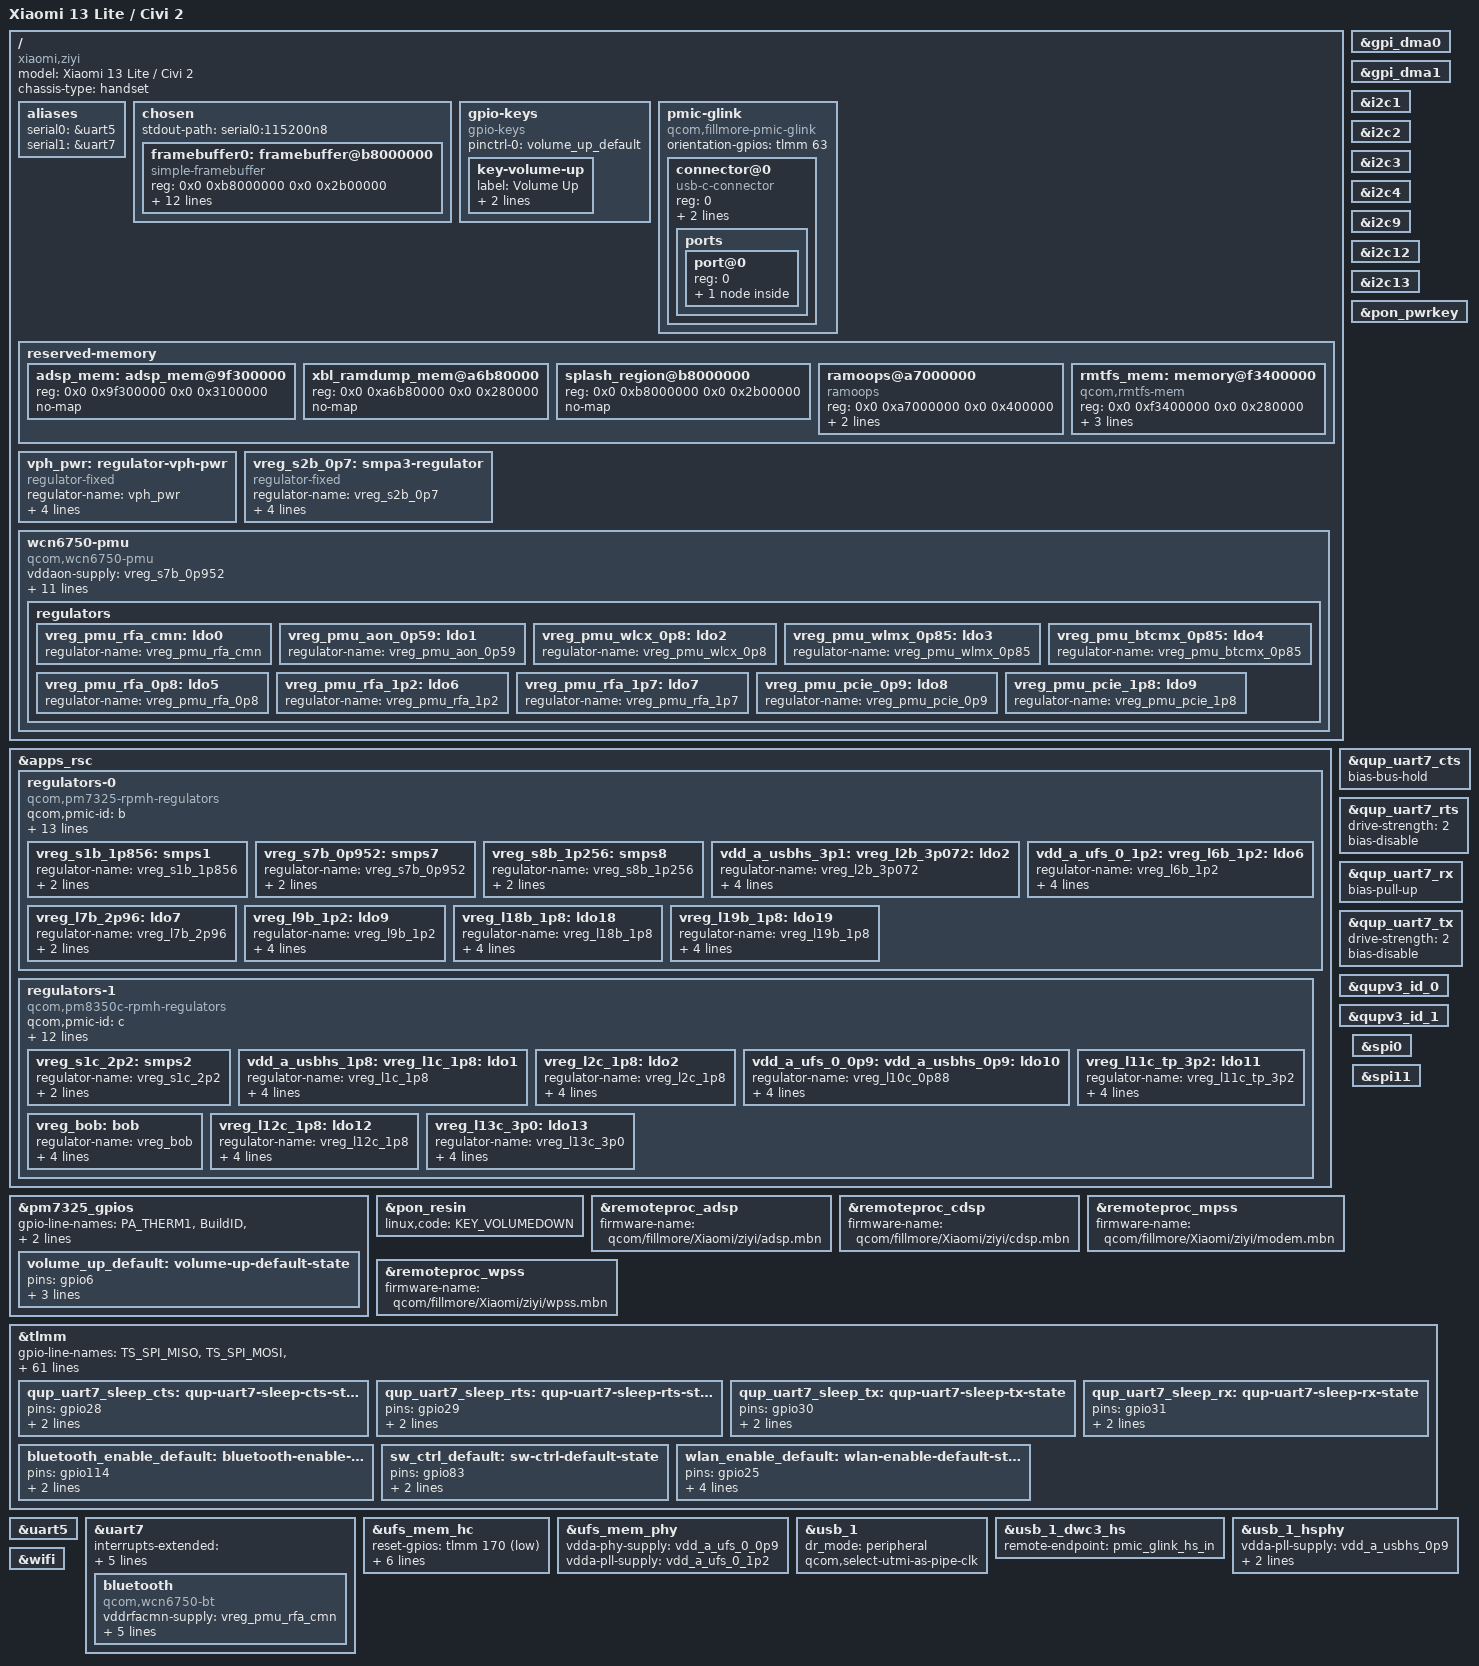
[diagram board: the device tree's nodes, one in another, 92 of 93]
// SPDX-License-Identifier: GPL-2.0-only
/*
 * Copyright (c) 2025, Aelin Reidel <aelin@mainlining.org>
 */

/dts-v1/;

#include <dt-bindings/pinctrl/qcom,pmic-gpio.h>
#include <dt-bindings/regulator/qcom,rpmh-regulator.h>
#include "fillmore.dtsi"
#include "pm7325.dtsi"
#include "pm8350c.dtsi"
#include "pmk8350.dtsi"

/delete-node/ &adsp_mem;
/delete-node/ &rmtfs_mem;
/delete-node/ &xbl_ramdump_mem;

/ {
	model = "Xiaomi 13 Lite / Civi 2";
	compatible = "xiaomi,ziyi", "qcom,fillmore";
	chassis-type = "handset";

	aliases {
		serial0 = &uart5;
		serial1 = &uart7;
	};

	chosen {
		#address-cells = <2>;
		#size-cells = <2>;
		ranges;

		stdout-path = "serial0:115200n8";

		framebuffer0: framebuffer@b8000000 {
			compatible = "simple-framebuffer";
			reg = <0x0 0xb8000000 0x0 0x2b00000>;
			width = <1080>;
			height = <2400>;
			stride = <(1080 * 4)>;
			format = "a8r8g8b8";

			clocks = <&gcc GCC_DISP_HF_AXI_CLK>,
				 <&gcc GCC_DISP_SF_AXI_CLK>,
				 <&dispcc DISP_CC_MDSS_MDP_CLK>,
				 <&dispcc DISP_CC_MDSS_BYTE0_CLK>,
				 <&dispcc DISP_CC_MDSS_BYTE0_INTF_CLK>,
				 <&dispcc DISP_CC_MDSS_PCLK0_CLK>,
				 <&dispcc DISP_CC_MDSS_VSYNC_CLK>;
			power-domains = <&dispcc DISP_CC_MDSS_CORE_GDSC>;
		};
	};

	gpio-keys {
		compatible = "gpio-keys";

		pinctrl-0 = <&volume_up_default>;
		pinctrl-names = "default";

		key-volume-up {
			label = "Volume Up";
			gpios = <&pm7325_gpios 6 GPIO_ACTIVE_LOW>;
			linux,code = <KEY_VOLUMEUP>;
		};
	};

	pmic-glink {
		compatible = "qcom,fillmore-pmic-glink",
			     "qcom,sm8450-pmic-glink",
			     "qcom,pmic-glink";
		#address-cells = <1>;
		#size-cells = <0>;
		orientation-gpios = <&tlmm 63 GPIO_ACTIVE_HIGH>;

		connector@0 {
			compatible = "usb-c-connector";
			reg = <0>;

			power-role = "dual";
			data-role = "dual";

			ports {
				#address-cells = <1>;
				#size-cells = <0>;

				port@0 {
					reg = <0>;

					pmic_glink_hs_in: endpoint {
						remote-endpoint = <&usb_1_dwc3_hs>;
					};
				};
			};
		};
	};

	reserved-memory {
		adsp_mem: adsp_mem@9f300000 {
			reg = <0x0 0x9f300000 0x0 0x3100000>;
			no-map;
		};

		xbl_ramdump_mem@a6b80000 {
			reg = <0x0 0xa6b80000 0x0 0x280000>;
			no-map;
		};

		splash_region@b8000000 {
			reg = <0x0 0xb8000000 0x0 0x2b00000>;
			no-map;
		};

		ramoops@a7000000 {
			compatible = "ramoops";
			reg = <0x0 0xa7000000 0x0 0x400000>;
			console-size = <0x200000>;
			pmsg-size = <0x200000>;
		};

		rmtfs_mem: memory@f3400000 {
			compatible = "qcom,rmtfs-mem";
			reg = <0x0 0xf3400000 0x0 0x280000>;
			no-map;

			qcom,client-id = <1>;
			qcom,vmid = <QCOM_SCM_VMID_MSS_MSA>;
		};
	};

	vph_pwr: regulator-vph-pwr {
		compatible = "regulator-fixed";

		regulator-name = "vph_pwr";
		regulator-min-microvolt = <3700000>;
		regulator-max-microvolt = <3700000>;

		regulator-always-on;
		regulator-boot-on;
	};

	/* S2B is really ebi.lvl but it's there for supply map completeness sake */
	vreg_s2b_0p7: smpa3-regulator {
		compatible = "regulator-fixed";
		regulator-name = "vreg_s2b_0p7";

		regulator-min-microvolt = <65535>;
		regulator-max-microvolt = <65535>;
		regulator-always-on;
		vin-supply = <&vph_pwr>;
	};

	wcn6750-pmu {
		compatible = "qcom,wcn6750-pmu";

		vddaon-supply = <&vreg_s7b_0p952>;
		vddasd-supply = <&vreg_l11c_tp_3p2>;
		vddpmu-supply = <&vreg_s7b_0p952>;
		vddrfa0p8-supply = <&vreg_s7b_0p952>;
		vddrfa1p2-supply = <&vreg_s8b_1p256>;
		vddrfa1p7-supply = <&vreg_s1b_1p856>;
		vddrfa2p2-supply = <&vreg_s1c_2p2>;

		wlan-enable-gpios = <&tlmm 25 GPIO_ACTIVE_HIGH>;
		bt-enable-gpios = <&tlmm 114 GPIO_ACTIVE_HIGH>;
		swctrl-gpios = <&tlmm 83 GPIO_ACTIVE_HIGH>;

		pinctrl-0 = <&bluetooth_enable_default>, <&wlan_enable_default>, <&sw_ctrl_default>;
		pinctrl-names = "default";

		regulators {
			vreg_pmu_rfa_cmn: ldo0 {
				regulator-name = "vreg_pmu_rfa_cmn";
			};

			vreg_pmu_aon_0p59: ldo1 {
				regulator-name = "vreg_pmu_aon_0p59";
			};

			vreg_pmu_wlcx_0p8: ldo2 {
				regulator-name = "vreg_pmu_wlcx_0p8";
			};

			vreg_pmu_wlmx_0p85: ldo3 {
				regulator-name = "vreg_pmu_wlmx_0p85";
			};

			vreg_pmu_btcmx_0p85: ldo4 {
				regulator-name = "vreg_pmu_btcmx_0p85";
			};

			vreg_pmu_rfa_0p8: ldo5 {
				regulator-name = "vreg_pmu_rfa_0p8";
			};

			vreg_pmu_rfa_1p2: ldo6 {
				regulator-name = "vreg_pmu_rfa_1p2";
			};

			vreg_pmu_rfa_1p7: ldo7 {
				regulator-name = "vreg_pmu_rfa_1p7";
			};

			vreg_pmu_pcie_0p9: ldo8 {
				regulator-name = "vreg_pmu_pcie_0p9";
			};

			vreg_pmu_pcie_1p8: ldo9 {
				regulator-name = "vreg_pmu_pcie_1p8";
			};
		};
	};
};

&apps_rsc {
	regulators-0 {
		compatible = "qcom,pm7325-rpmh-regulators";
		qcom,pmic-id = "b";

		vdd-s1-supply = <&vph_pwr>;
		vdd-s2-supply = <&vph_pwr>;
		vdd-s7-supply = <&vph_pwr>;
		vdd-s8-supply = <&vph_pwr>;

		vdd-l1-l4-l12-l15-supply = <&vreg_s7b_0p952>;
		vdd-l2-l7-supply = <&vreg_bob>;
		vdd-l3-supply = <&vreg_s2b_0p7>;
		vdd-l5-supply = <&vreg_s2b_0p7>;
		vdd-l6-l9-l10-supply = <&vreg_s8b_1p256>;
		vdd-l8-supply = <&vreg_s7b_0p952>;
		vdd-l11-l17-l18-l19-supply = <&vreg_s1b_1p856>;
		vdd-l13-supply = <&vreg_s7b_0p952>;
		vdd-l14-l16-supply = <&vreg_s8b_1p256>;

		/*
		 * S2, L4-L5 are ARCs:
		 * S2 - ebi.lvl,
		 * L4 - lmx.lvl,
		 * l5 - lcx.lvl.
		 *
		 * L10 is unused.
		 */

		vreg_s1b_1p856: smps1 {
			regulator-name = "vreg_s1b_1p856";
			regulator-min-microvolt = <1700000>;
			regulator-max-microvolt = <2040000>;
		};

		vreg_s7b_0p952: smps7 {
			regulator-name = "vreg_s7b_0p952";
			regulator-min-microvolt = <598000>;
			regulator-max-microvolt = <1120000>;
		};

		vreg_s8b_1p256: smps8 {
			regulator-name = "vreg_s8b_1p256";
			regulator-min-microvolt = <382000>;
			regulator-max-microvolt = <1510000>;
		};

		vdd_a_usbhs_3p1:
		vreg_l2b_3p072: ldo2 {
			regulator-name = "vreg_l2b_3p072";
			regulator-min-microvolt = <2700000>;
			regulator-max-microvolt = <3544000>;
			regulator-initial-mode = <RPMH_REGULATOR_MODE_HPM>;
		};

		vdd_a_ufs_0_1p2:
		vreg_l6b_1p2: ldo6 {
			regulator-name = "vreg_l6b_1p2";
			regulator-min-microvolt = <1140000>;
			regulator-max-microvolt = <1260000>;
			regulator-initial-mode = <RPMH_REGULATOR_MODE_HPM>;
		};

		vreg_l7b_2p96: ldo7 {
			regulator-name = "vreg_l7b_2p96";
			/*
			 * Remove min/max voltages for this regulator as initial
			 * voltage of L7B is set to be 2.504v/2.952v during PON
			 * depending upon the UFS mode 3.x/2.x. UFS is the only
			 * client on this and this regulator will only be voted
			 * for enabling/disabling conditions.
			 */
			regulator-initial-mode = <RPMH_REGULATOR_MODE_HPM>;
		};

		vreg_l9b_1p2: ldo9 {
			regulator-name = "vreg_l9b_1p2";
			regulator-min-microvolt = <1080000>;
			regulator-max-microvolt = <1304000>;
			regulator-initial-mode = <RPMH_REGULATOR_MODE_HPM>;
		};

		vreg_l18b_1p8: ldo18 {
			regulator-name = "vreg_l18b_1p8";
			regulator-min-microvolt = <1504000>;
			regulator-max-microvolt = <2000000>;
			regulator-initial-mode = <RPMH_REGULATOR_MODE_HPM>;
		};

		vreg_l19b_1p8: ldo19 {
			regulator-name = "vreg_l19b_1p8";
			regulator-min-microvolt = <1700000>;
			regulator-max-microvolt = <1950000>;
			regulator-initial-mode = <RPMH_REGULATOR_MODE_HPM>;
		};
	};

	regulators-1 {
		compatible = "qcom,pm8350c-rpmh-regulators";
		qcom,pmic-id = "c";

		vdd-s1-supply = <&vph_pwr>;
		vdd-s2-supply = <&vph_pwr>;
		vdd-s5-supply = <&vph_pwr>;
		vdd-s7-supply = <&vph_pwr>;
		vdd-s9-supply = <&vph_pwr>;
		vdd-s10-supply = <&vph_pwr>;

		vdd-l1-l12-supply = <&vreg_s1b_1p856>;
		vdd-l2-l8-supply = <&vreg_s1b_1p856>;
		vdd-l3-l4-l5-l7-l13-supply = <&vreg_bob>;
		vdd-l6-l9-l11-supply = <&vreg_bob>;
		vdd-l10-supply = <&vreg_s7b_0p952>;

		vdd-bob-supply = <&vph_pwr>;

		/*
		 * S2, S4, S5, S6, S8, S10 are ARCs:
		 * S2  - gfx.lvl,
		 * S4  - mxc.lvl,
		 * S5  - mmcx.lvl,
		 * S6  - mms.lvl,
		 * S8  - cx.lvl,
		 * S10 - mx.lvl.
		 */

		vreg_s1c_2p2: smps2 {
			regulator-name = "vreg_s1c_2p2";
			regulator-min-microvolt = <850000>;
			regulator-max-microvolt = <2200000>;
		};

		vdd_a_usbhs_1p8:
		vreg_l1c_1p8: ldo1 {
			regulator-name = "vreg_l1c_1p8";
			regulator-min-microvolt = <1620000>;
			regulator-max-microvolt = <1980000>;
			regulator-initial-mode = <RPMH_REGULATOR_MODE_HPM>;
		};

		vreg_l2c_1p8: ldo2 {
			regulator-name = "vreg_l2c_1p8";
			regulator-min-microvolt = <1620000>;
			regulator-max-microvolt = <1980000>;
			regulator-initial-mode = <RPMH_REGULATOR_MODE_HPM>;
		};

		vdd_a_ufs_0_0p9:
		vdd_a_usbhs_0p9:
		vreg_l10c_0p88: ldo10 {
			regulator-name = "vreg_l10c_0p88";
			regulator-min-microvolt = <720000>;
			regulator-max-microvolt = <1050000>;
			regulator-initial-mode = <RPMH_REGULATOR_MODE_HPM>;
		};

		vreg_l11c_tp_3p2: ldo11 {
			regulator-name = "vreg_l11c_tp_3p2";
			regulator-min-microvolt = <1650000>;
			regulator-max-microvolt = <3544000>;
			regulator-initial-mode = <RPMH_REGULATOR_MODE_HPM>;
		};

		vreg_bob: bob {
			regulator-name = "vreg_bob";
			regulator-min-microvolt = <3008000>;
			regulator-max-microvolt = <3960000>;
			regulator-initial-mode = <RPMH_REGULATOR_MODE_AUTO>;
		};

		vreg_l12c_1p8: ldo12 {
			regulator-name = "vreg_l12c_1p8";
			regulator-min-microvolt = <1650000>;
			regulator-max-microvolt = <2000000>;
			regulator-initial-mode = <RPMH_REGULATOR_MODE_HPM>;
		};

		vreg_l13c_3p0: ldo13 {
			regulator-name = "vreg_l13c_3p0";
			regulator-min-microvolt = <2700000>;
			regulator-max-microvolt = <3300000>;
			regulator-initial-mode = <RPMH_REGULATOR_MODE_HPM>;
		};
	};
};

&gpi_dma0 {
	status = "okay";
};

&gpi_dma1 {
	status = "okay";
};

&i2c1 {
	/* qcom,cam-i2c-flash @ 7 */
	/* awinic haptics @ 58 */

	status = "okay";
};

&i2c2 {
	/* pm8008i @ 8 */
	/* pm8008i @ 9 */
	/* pm8010j @ c */
	/* pm8010j @ d */
	/* fsa4480 @ 42 */
	/* rtc6226 @ 64 */

	status = "okay";
};

&i2c3 {
	/* qcom,cam-i2c-flash @ 6 */
	/* awinic,aw2033_led @ 45 */

	status = "okay";
};

&i2c4 {
	/* richtek,rt1711h @ 4e */
	/* lionsemi,ln8000-master @ 51 */
	/* ti,bq2589x-charger @ 5a */

	status = "okay";
};

&i2c9 {
	/* qcom,sn-nci @ 28 */

	status = "okay";
};

&i2c12 {
	/* lionsemi,ln8000-slave @ 51 */
	/* ti,bq27z561 @ 55 */

	status = "okay";
};

&i2c13 {
	/* awinic,aw882xx_smartpa @ 35 */

	status = "okay";
};

&pm7325_gpios {
	gpio-line-names = "PA_THERM1", /* GPIO_1 */
			  "BuildID",
			  "ProjectID",
			  "PA_THERM2",
			  "CBL_PWR_N",
			  "KYPD_VOLP_N",
			  "NC",
			  "NC",
			  "NC",
			  "GND"; /* GPIO_10 */

	volume_up_default: volume-up-default-state {
		pins = "gpio6";
		function = PMIC_GPIO_FUNC_NORMAL;
		power-source = <1>;
		bias-pull-up;
	};
};

&pon_pwrkey {
	status = "okay";
};

&pon_resin {
	linux,code = <KEY_VOLUMEDOWN>;

	status = "okay";
};

&qup_uart7_cts {
	/*
	 * Configure a bias-bus-hold on CTS to lower power
	 * usage when Bluetooth is turned off. Bus hold will
	 * maintain a low power state regardless of whether
	 * the Bluetooth module drives the pin in either
	 * direction or leaves the pin fully unpowered.
	 */
	bias-bus-hold;
};

&qup_uart7_rts {
	/* We'll drive RTS, so no pull */
	drive-strength = <2>;
	bias-disable;
};

&qup_uart7_rx {
	/*
	 * Configure a pull-up on RX. This is needed to avoid
	 * garbage data when the TX pin of the Bluetooth module is
	 * in tri-state (module powered off or not driving the
	 * signal yet).
	 */
	bias-pull-up;
};

&qup_uart7_tx {
	/* We'll drive TX, so no pull */
	drive-strength = <2>;
	bias-disable;
};

&qupv3_id_0 {
	status = "okay";
};

&qupv3_id_1 {
	status = "okay";
};

&remoteproc_adsp {
	firmware-name = "qcom/fillmore/Xiaomi/ziyi/adsp.mbn";

	status = "okay";
};

&remoteproc_cdsp {
	firmware-name = "qcom/fillmore/Xiaomi/ziyi/cdsp.mbn";

	status = "okay";
};

&remoteproc_mpss {
	firmware-name = "qcom/fillmore/Xiaomi/ziyi/modem.mbn";

	status = "okay";
};

&remoteproc_wpss {
	firmware-name = "qcom/fillmore/Xiaomi/ziyi/wpss.mbn";

	status = "okay";
};

&spi0 {
	/* syna,s3908 @ 0 */

	status = "okay";
};

&spi11 {
	/* ir-spi @ 0 */

	status = "okay";
};

&tlmm {
	gpio-line-names = "TS_SPI_MISO", /* GPIO_0 */
			  "TS_SPI_MOSI",
			  "TS_SPI_CLK",
			  "TS_SPI_CS",
			  "SOFT_LED_R_HAP_I2C_SDA",
			  "SOFT_LED_R_HAP_I2C_SCL",
			  "NC",
			  "LCD_ID_DET1",
			  "APPS_I2C_SDA",
			  "APPS_I2C_SCL",
			  "HAP_INT_N", /* GPIO_10 */
			  "ERR_INT_N",
			  "SOFT_LED_L_RGB_I2C_SDA",
			  "SOFT_LED_L_RGB_I2C_SCL",
			  "SOFT_LED_TORCH",
			  "SOFT_LED_EN",
			  "SC8551_1_PD_CHG_I2C_SDA",
			  "SC8551_1_PD_CHG_I2C_SCL",
			  "NC",
			  "SY6970D_INT",
			  "CAMF1_RESET_N", /* GPIO_20 */
			  "CAMW_RESET_N",
			  "DEBUG_UART_TX",
			  "DEBUG_UART_RX",
			  "GNSS_L1_ELNA_EN",
			  "MOS_WLAN_EN",
			  "PM8008_IRQ_1",
			  "VBUS_NTC_CTRL",
			  "MOS_BT_UART_CTS",
			  "MOS_BT_UART_RFR",
			  "MOS_BT_UART_TX", /* GPIO_30 */
			  "MOS_BT_UART_RX",
			  "NFC_SE_SPI_MISO",
			  "NFC_SE_SPI_MOSI",
			  "NFC_SE_SPI_CLK",
			  "NFC_SE_SPI_CS",
			  "NFC_I2C_SDA",
			  "NFC_I2C_SCL",
			  "NFC_EN",
			  "NFC_CLK_REQ",
			  "NFC_DWL_REQ", /* GPIO_40 */
			  "NFC_INT_REQ",
			  "LCD_RESET_N",
			  "FPS_INT_N",
			  "NC",
			  "INFRARED_SPI_MOSI",
			  "NC",
			  "NC",
			  "SC8551_2_FG_I2C_SDA",
			  "SC8551_2_FG_I2C_SCL",
			  "SBU_UART_EN", /* GPIO_50 */
			  "TS_INT_N",
			  "SPKR_I2C_SDA",
			  "SPKR_I2C_SCL",
			  "WCD_RESET_N",
			  "NC",
			  "FPS_SPI_MISO",
			  "FPS_SPI_MOSI",
			  "FPS_SPI_CLK",
			  "FPS_SPI_CS_N",
			  "CAMW_DVDD_LDO_EN", /* GPIO_60 */
			  "CAMT_AVDD_LDO_EN",
			  "CAMU_AVDD_LDO_EN",
			  "CHG_OTG",
			  "CAMF1_MCLK0",
			  "CAMW_MCLK1",
			  "CAMT_MCLK2",
			  "CAMU_MCLK3",
			  "CAMF2_MCLK4",
			  "CAMU_DVDD_LDO_EN",
			  "CCI_I2C0_SDA", /* GPIO_70 */
			  "CCI_I2C0_SCL",
			  "CCI_I2C1_SDA",
			  "CCI_I2C1_SCL",
			  "CCI_I2C2_SDA",
			  "CCI_I2C2_SCL",
			  "CCI_I2C3_SDA",
			  "CCI_I2C3_SCL",
			  "CAMT_RESET_N",
			  "CAMU_RESET_N",
			  "CAMF2_RESET_N", /* GPIO_80 */
			  "EINT_CC",
			  "MDP_VSYNC_P",
			  "MOS_SW_CTRL",
			  "UIM1_DATA",
			  "UIM1_CLK",
			  "UIM1_RESET",
			  "UIM1_UIM2_PRESENT_DET",
			  "UIM2_DATA",
			  "UIM2_CLK",
			  "UIM2_RESET", /* GPIO_90 */
			  "UIM1_UIM2_PRESENT_DET",
			  "QLINK0_REQ",
			  "QLINK0_EN",
			  "QLINK0_WMSS_RESET_N",
			  "NC",
			  "NC",
			  "NC",
			  "NC",
			  "CAMW_AVDD_LDO_EN",
			  "NC", /* GPIO_100 */
			  "SDM_RFFE0_CLK",
			  "SDM_RFFE0_DATA",
			  "SDM_RFFE1_CLK",
			  "SDM_RFFE1_DATA",
			  "NC",
			  "MOS_AS_EN",
			  "NC",
			  "NC",
			  "SDM_RFFE4_CLK",
			  "SDM_RFFE4_DATA", /* GPIO_110 */
			  "WLAN_COEX_UART_TX",
			  "WLAN_COEX_UART_RX",
			  "NC",
			  "MOS_BT_EN",
			  "NC",
			  "NC",
			  "PCIE0_RESET_N",
			  "PCIE0_CLK_REQ_N",
			  "PCIE0_WAKE_N",
			  "1P8", /* Connected to pm7325_l18, GPIO_120 */
			  "FORCED_USB_BOOT",
			  "SC8551_INT_MASTER",
			  "WLAN2HOST_SOL",
			  "HOST2WLAN_SOL",
			  "SC8551_INT_SLAVE",
			  "TS_RESET_N",
			  "SPKR_I2S_BCK",
			  "SPKR_I2S_DIN",
			  "SPKR_I2S_DOUT",
			  "SPKR_I2S_WS", /* GPIO_130 */
			  "WCD_SWR_TX_CLK",
			  "WCD_SWR_TX_DATA0",
			  "WCD_SWR_TX_DATA1",
			  "WCD_SWR_RX_CLK",
			  "WCD_SWR_RX_DATA0",
			  "WCD_SWR_RX_DATA1",
			  "NC",
			  "NC",
			  "NC",
			  "GYRO_INT_N", /* GPIO_140 */
			  "FPS_RESET_N",
			  "NC",
			  "NC",
			  "NC",
			  "WCD_SWR_TX_DATA2",
			  "HAP_RESET_N",
			  "USB0_CC_DIR",
			  "OLED_DDIC_1P2_EN",
			  "NC",
			  "MOS_BT_WLAN_SLIMBUS_CLK", /* GPIO_150 */
			  "MOS_BT_WLAN_SLIMBUS_DATA0",
			  "NC",
			  "SPKR_BOT_INT",
			  "ALS_REAR_I2C_SDA",
			  "ALS_REAR_I2C_SCL",
			  "ALS_FRO_I2C_SDA",
			  "ALS_FRO_I2C_SCL",
			  "MAG_SAR_I2C_SDA",
			  "MAG_SAR_I2C_SCL",
			  "NC", /* GPIO_160 */
			  "ACCEL_INT_N",
			  "A+G_SPI_MISO",
			  "A+G_SPI_MOSI",
			  "A+G_SPI_CLK",
			  "A+G_SPI_CS_N",
			  "BTLE_UART_TX",
			  "BTLE_UART_RX",
			  "NC",
			  "ALS_FRO_INT_N"; /* GPIO_169 */

	gpio-reserved-ranges = <32 4>, /* NFC secure element */
			       <56 4>; /* Fingerprint SPI */

	qup_uart7_sleep_cts: qup-uart7-sleep-cts-state {
		pins = "gpio28";
		function = "gpio";
		/*
		 * Configure a bias-bus-hold on CTS to lower power
		 * usage when Bluetooth is turned off. Bus hold will
		 * maintain a low power state regardless of whether
		 * the Bluetooth module drives the pin in either
		 * direction or leaves the pin fully unpowered.
		 */
		bias-bus-hold;
	};

	qup_uart7_sleep_rts: qup-uart7-sleep-rts-state {
		pins = "gpio29";
		function = "gpio";
		/*
		 * Configure pull-down on RTS. As RTS is active low
		 * signal, pull it low to indicate the BT SoC that it
		 * can wakeup the system anytime from suspend state by
		 * pulling RX low (by sending wakeup bytes).
		 */
		bias-pull-down;
	};

	qup_uart7_sleep_tx: qup-uart7-sleep-tx-state {
		pins = "gpio30";
		function = "gpio";
		/*
		 * Configure pull-up on TX when it isn't actively driven
		 * to prevent BT SoC from receiving garbage during sleep.
		 */
		bias-pull-up;
	};

	qup_uart7_sleep_rx: qup-uart7-sleep-rx-state {
		pins = "gpio31";
		function = "gpio";
		/*
		 * Configure a pull-up on RX. This is needed to avoid
		 * garbage data when the TX pin of the Bluetooth module
		 * is floating which may cause spurious wakeups.
		 */
		bias-pull-up;
	};

	bluetooth_enable_default: bluetooth-enable-default-state {
		pins = "gpio114";
		function = "gpio";
		bias-pull-down;
	};

	sw_ctrl_default: sw-ctrl-default-state {
		pins = "gpio83";
		function = "gpio";
		bias-pull-down;
	};

	wlan_enable_default: wlan-enable-default-state {
		pins = "gpio25";
		function = "gpio";
		drive-strength = <16>;
		output-high;
		bias-pull-up;
	};
};

&uart5 {
	status = "okay";
};

&uart7 {
	/delete-property/ interrupts;
	interrupts-extended = <&intc GIC_SPI 608 IRQ_TYPE_LEVEL_HIGH>,
			      <&tlmm 31 IRQ_TYPE_EDGE_FALLING>;

	pinctrl-1 =  <&qup_uart7_sleep_cts>,
		     <&qup_uart7_sleep_rts>,
		     <&qup_uart7_sleep_tx>,
		     <&qup_uart7_sleep_rx>;
	pinctrl-names = "default",
			"sleep";

	status = "okay";

	bluetooth {
		compatible = "qcom,wcn6750-bt";

		vddrfacmn-supply = <&vreg_pmu_rfa_cmn>;
		vddaon-supply = <&vreg_pmu_aon_0p59>;
		vddbtcmx-supply = <&vreg_pmu_btcmx_0p85>;
		vddrfa0p8-supply = <&vreg_pmu_rfa_0p8>;
		vddrfa1p7-supply = <&vreg_pmu_rfa_1p7>;
		vddrfa1p2-supply = <&vreg_pmu_rfa_1p2>;
	};
};

&ufs_mem_hc {
	reset-gpios = <&tlmm 170 GPIO_ACTIVE_LOW>;

	vcc-supply = <&vreg_l7b_2p96>;
	vcc-max-microamp = <1100000>;

	vccq-supply = <&vreg_l9b_1p2>;
	vccq-max-microamp = <1200000>;

	vccq2-supply = <&vreg_l19b_1p8>;
	vccq2-max-microamp = <800000>;

	status = "okay";
};

&ufs_mem_phy {
	vdda-phy-supply = <&vdd_a_ufs_0_0p9>;
	vdda-pll-supply = <&vdd_a_ufs_0_1p2>;

	status = "okay";
};

&usb_1 {
	dr_mode = "peripheral";

	/* USB 2.0 only, HW does not support USB 3.x */
	qcom,select-utmi-as-pipe-clk;

	status = "okay";
};

&usb_1_dwc3_hs {
	remote-endpoint = <&pmic_glink_hs_in>;
};

&usb_1_hsphy {
	vdda-pll-supply = <&vdd_a_usbhs_0p9>;
	vdda18-supply = <&vdd_a_usbhs_1p8>;
	vdda33-supply = <&vdd_a_usbhs_3p1>;

	status = "okay";
};

&wifi {
	//qcom,calibration-variant = "Xiaomi_13_Lite";

	status = "okay";
};
